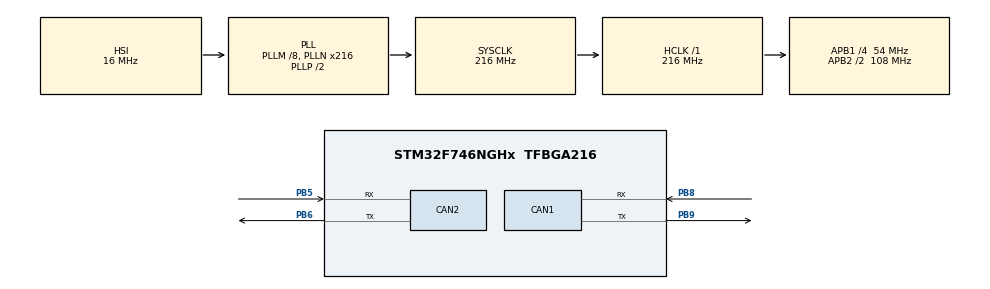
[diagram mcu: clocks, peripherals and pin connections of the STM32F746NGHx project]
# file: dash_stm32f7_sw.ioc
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CAN1.BS1=CAN_BS1_2TQ
CAN1.BS2=CAN_BS2_2TQ
CAN1.CalculateTimeQuantum=296.2962962962963
CAN1.SJW=CAN_SJW_1TQ
CAN2.BS1=CAN_BS1_2TQ
CAN2.BS2=CAN_BS2_2TQ
CAN2.CalculateTimeQuantum=296.2962962962963
Mcu.Family=STM32F7
Mcu.Name=STM32F746NGHx
Mcu.Package=TFBGA216
NVIC.PriorityGroup=NVIC_PRIORITYGROUP_4
NVIC.TIM1_UP_TIM10_IRQn=true\:0\:0\:false\:false\:true\:false\:true
NVIC.TimeBase=TIM1_UP_TIM10_IRQn
NVIC.TimeBaseIP=TIM1
PB5.Mode=Slave
PB5.Signal=CAN2_RX
PB6.Mode=Slave
PB6.Signal=CAN2_TX
PB8.Mode=Master
PB8.Signal=CAN1_RX
PB9.Mode=Master
PB9.Signal=CAN1_TX
ProjectManager.HeapSize=0x200
ProjectManager.StackSize=0x400
ProjectManager.TargetToolchain=Makefile
RCC.AHBFreq_Value=216000000
RCC.APB1CLKDivider=RCC_HCLK_DIV4
RCC.APB1Freq_Value=54000000
RCC.APB1TimFreq_Value=108000000
RCC.APB2CLKDivider=RCC_HCLK_DIV2
RCC.APB2Freq_Value=108000000
RCC.APB2TimFreq_Value=216000000
RCC.CortexFreq_Value=216000000
RCC.HCLKFreq_Value=216000000
RCC.HSE_VALUE=25000000
RCC.HSI_VALUE=16000000
RCC.LSE_VALUE=32768
RCC.PLL48CLockSelection=RCC_CLK48SOURCE_PLLSAIP
RCC.PLLI2SN=100
RCC.PLLM=8
RCC.PLLN=216
RCC.PLLQ=9
RCC.PLLSAIN=50
RCC.PLLSAIP=RCC_PLLSAIP_DIV8
RCC.SDMMCClockSelection=RCC_SDMMC1CLKSOURCE_CLK48
RCC.SYSCLKFreq_VALUE=216000000
RCC.SYSCLKSource=RCC_SYSCLKSOURCE_PLLCLK
RCC.USBFreq_Value=12500000
RCC.VCOOutputFreq_Value=432000000
VP_RTC_VS_RTC_Activate.Mode=RTC_Enabled
VP_SYS_VS_tim1.Mode=TIM1
VP_TIM2_VS_ClockSourceINT.Mode=Internal
board=32F746GDISCOVERY

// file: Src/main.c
/* USER CODE BEGIN Header */
/**
  ******************************************************************************
  * @file           : main.c
  * @brief          : Main program body
  ******************************************************************************
  * @attention
  *
  * <h2><center>&copy; Copyright (c) 2019 STMicroelectronics.
  * All rights reserved.</center></h2>
  *
  * This software component is licensed by ST under BSD 3-Clause license,
  * the "License"; You may not use this file except in compliance with the
  * License. You may obtain a copy of the License at:
  *                        opensource.org/licenses/BSD-3-Clause
  *
  ******************************************************************************
  */
/* USER CODE END Header */

#include "main.h"

/* USER CODE BEGIN Includes */
#include "../lv_conf.h"
#include "../lv_drv_conf.h"
/* USER CODE END Includes */

CAN_HandleTypeDef hcan1;
CAN_HandleTypeDef hcan2;

RTC_HandleTypeDef hrtc;

TIM_HandleTypeDef htim2;

void SystemClock_Config(void);
static void MX_GPIO_Init(void);
static void MX_RTC_Init(void);
static void MX_TIM2_Init(void);
static void MX_CAN1_Init(void);
static void MX_CAN2_Init(void);

int main(void)
{

  /* MCU Configuration--------------------------------------------------------*/

  /* Reset of all peripherals, Initializes the Flash interface and the Systick. */
  HAL_Init();

  /* Configure the system clock */
  SystemClock_Config();

  /* Initialize all configured peripherals */
  MX_GPIO_Init();
  MX_RTC_Init();
  MX_TIM2_Init();
  MX_CAN1_Init();
  MX_CAN2_Init();

  /* Infinite loop */
  while (1)
  {

  }
}

void SystemClock_Config(void)
{
  RCC_OscInitTypeDef RCC_OscInitStruct = {0};
  RCC_ClkInitTypeDef RCC_ClkInitStruct = {0};
  RCC_PeriphCLKInitTypeDef PeriphClkInitStruct = {0};

  /** Configure the main internal regulator output voltage
  */
  __HAL_RCC_PWR_CLK_ENABLE();
  __HAL_PWR_VOLTAGESCALING_CONFIG(PWR_REGULATOR_VOLTAGE_SCALE1);
  /** Initializes the CPU, AHB and APB busses clocks
  */
  RCC_OscInitStruct.OscillatorType = RCC_OSCILLATORTYPE_HSI|RCC_OSCILLATORTYPE_LSI;
  RCC_OscInitStruct.HSIState = RCC_HSI_ON;
  RCC_OscInitStruct.HSICalibrationValue = RCC_HSICALIBRATION_DEFAULT;
  RCC_OscInitStruct.LSIState = RCC_LSI_ON;
  RCC_OscInitStruct.PLL.PLLState = RCC_PLL_ON;
  RCC_OscInitStruct.PLL.PLLSource = RCC_PLLSOURCE_HSI;
  RCC_OscInitStruct.PLL.PLLM = 8;
  RCC_OscInitStruct.PLL.PLLN = 216;
  RCC_OscInitStruct.PLL.PLLP = RCC_PLLP_DIV2;
  RCC_OscInitStruct.PLL.PLLQ = 9;
  if (HAL_RCC_OscConfig(&RCC_OscInitStruct) != HAL_OK)
  {
    Error_Handler();
  }
  /** Activate the Over-Drive mode
  */
  if (HAL_PWREx_EnableOverDrive() != HAL_OK)
  {
    Error_Handler();
  }
  /** Initializes the CPU, AHB and APB busses clocks
  */
  RCC_ClkInitStruct.ClockType = RCC_CLOCKTYPE_HCLK|RCC_CLOCKTYPE_SYSCLK
                              |RCC_CLOCKTYPE_PCLK1|RCC_CLOCKTYPE_PCLK2;
  RCC_ClkInitStruct.SYSCLKSource = RCC_SYSCLKSOURCE_PLLCLK;
  RCC_ClkInitStruct.AHBCLKDivider = RCC_SYSCLK_DIV1;
  RCC_ClkInitStruct.APB1CLKDivider = RCC_HCLK_DIV4;
  RCC_ClkInitStruct.APB2CLKDivider = RCC_HCLK_DIV2;

  if (HAL_RCC_ClockConfig(&RCC_ClkInitStruct, FLASH_LATENCY_7) != HAL_OK)
  {
    Error_Handler();
  }
  PeriphClkInitStruct.PeriphClockSelection = RCC_PERIPHCLK_RTC;
  PeriphClkInitStruct.RTCClockSelection = RCC_RTCCLKSOURCE_LSI;
  if (HAL_RCCEx_PeriphCLKConfig(&PeriphClkInitStruct) != HAL_OK)
  {
    Error_Handler();
  }
}

static void MX_CAN1_Init(void)
{

  hcan1.Instance = CAN1;
  hcan1.Init.Prescaler = 16;
  hcan1.Init.Mode = CAN_MODE_NORMAL;
  hcan1.Init.SyncJumpWidth = CAN_SJW_1TQ;
  hcan1.Init.TimeSeg1 = CAN_BS1_2TQ;
  hcan1.Init.TimeSeg2 = CAN_BS2_2TQ;
  hcan1.Init.TimeTriggeredMode = DISABLE;
  hcan1.Init.AutoBusOff = DISABLE;
  hcan1.Init.AutoWakeUp = DISABLE;
  hcan1.Init.AutoRetransmission = DISABLE;
  hcan1.Init.ReceiveFifoLocked = DISABLE;
  hcan1.Init.TransmitFifoPriority = DISABLE;
  if (HAL_CAN_Init(&hcan1) != HAL_OK)
  {
    Error_Handler();
  }

}

static void MX_CAN2_Init(void)
{

  hcan2.Instance = CAN2;
  hcan2.Init.Prescaler = 16;
  hcan2.Init.Mode = CAN_MODE_NORMAL;
  hcan2.Init.SyncJumpWidth = CAN_SJW_1TQ;
  hcan2.Init.TimeSeg1 = CAN_BS1_2TQ;
  hcan2.Init.TimeSeg2 = CAN_BS2_2TQ;
  hcan2.Init.TimeTriggeredMode = DISABLE;
  hcan2.Init.AutoBusOff = DISABLE;
  hcan2.Init.AutoWakeUp = DISABLE;
  hcan2.Init.AutoRetransmission = DISABLE;
  hcan2.Init.ReceiveFifoLocked = DISABLE;
  hcan2.Init.TransmitFifoPriority = DISABLE;
  if (HAL_CAN_Init(&hcan2) != HAL_OK)
  {
    Error_Handler();
  }

}

static void MX_RTC_Init(void)
{

  /** Initialize RTC Only
  */
  hrtc.Instance = RTC;
  hrtc.Init.HourFormat = RTC_HOURFORMAT_24;
  hrtc.Init.AsynchPrediv = 127;
  hrtc.Init.SynchPrediv = 255;
  hrtc.Init.OutPut = RTC_OUTPUT_DISABLE;
  hrtc.Init.OutPutPolarity = RTC_OUTPUT_POLARITY_HIGH;
  hrtc.Init.OutPutType = RTC_OUTPUT_TYPE_OPENDRAIN;
  if (HAL_RTC_Init(&hrtc) != HAL_OK)
  {
    Error_Handler();
  }

}

static void MX_TIM2_Init(void)
{

  TIM_ClockConfigTypeDef sClockSourceConfig = {0};
  TIM_MasterConfigTypeDef sMasterConfig = {0};

  htim2.Instance = TIM2;
  htim2.Init.Prescaler = 0;
  htim2.Init.CounterMode = TIM_COUNTERMODE_UP;
  htim2.Init.Period = 0;
  htim2.Init.ClockDivision = TIM_CLOCKDIVISION_DIV1;
  htim2.Init.AutoReloadPreload = TIM_AUTORELOAD_PRELOAD_DISABLE;
  if (HAL_TIM_Base_Init(&htim2) != HAL_OK)
  {
    Error_Handler();
  }
  sClockSourceConfig.ClockSource = TIM_CLOCKSOURCE_INTERNAL;
  if (HAL_TIM_ConfigClockSource(&htim2, &sClockSourceConfig) != HAL_OK)
  {
    Error_Handler();
  }
  sMasterConfig.MasterOutputTrigger = TIM_TRGO_RESET;
  sMasterConfig.MasterSlaveMode = TIM_MASTERSLAVEMODE_DISABLE;
  if (HAL_TIMEx_MasterConfigSynchronization(&htim2, &sMasterConfig) != HAL_OK)
  {
    Error_Handler();
  }

}

static void MX_GPIO_Init(void)
{
  GPIO_InitTypeDef GPIO_InitStruct = {0};

  /* GPIO Ports Clock Enable */
  __HAL_RCC_GPIOE_CLK_ENABLE();
  __HAL_RCC_GPIOG_CLK_ENABLE();
  __HAL_RCC_GPIOB_CLK_ENABLE();
  __HAL_RCC_GPIOD_CLK_ENABLE();
  __HAL_RCC_GPIOC_CLK_ENABLE();
  __HAL_RCC_GPIOA_CLK_ENABLE();
  __HAL_RCC_GPIOJ_CLK_ENABLE();
  __HAL_RCC_GPIOI_CLK_ENABLE();
  __HAL_RCC_GPIOK_CLK_ENABLE();
  __HAL_RCC_GPIOF_CLK_ENABLE();
  __HAL_RCC_GPIOH_CLK_ENABLE();

  /*Configure GPIO pins : PE4 PE3 PE2 PE1
                           PE0 PE5 PE6 PE8
                           PE9 PE11 PE14 PE7
                           PE10 PE12 PE15 PE13 */
  GPIO_InitStruct.Pin = GPIO_PIN_4|GPIO_PIN_3|GPIO_PIN_2|GPIO_PIN_1
                          |GPIO_PIN_0|GPIO_PIN_5|GPIO_PIN_6|GPIO_PIN_8
                          |GPIO_PIN_9|GPIO_PIN_11|GPIO_PIN_14|GPIO_PIN_7
                          |GPIO_PIN_10|GPIO_PIN_12|GPIO_PIN_15|GPIO_PIN_13;
  GPIO_InitStruct.Mode = GPIO_MODE_ANALOG;
  GPIO_InitStruct.Pull = GPIO_NOPULL;
  HAL_GPIO_Init(GPIOE, &GPIO_InitStruct);

  /*Configure GPIO pins : PG14 PG13 PG15 PG11
                           PG12 PG10 PG9 PG8
                           PG7 PG6 PG1 PG3
                           PG2 PG0 PG5 PG4 */
  GPIO_InitStruct.Pin = GPIO_PIN_14|GPIO_PIN_13|GPIO_PIN_15|GPIO_PIN_11
                          |GPIO_PIN_12|GPIO_PIN_10|GPIO_PIN_9|GPIO_PIN_8
                          |GPIO_PIN_7|GPIO_PIN_6|GPIO_PIN_1|GPIO_PIN_3
                          |GPIO_PIN_2|GPIO_PIN_0|GPIO_PIN_5|GPIO_PIN_4;
  GPIO_InitStruct.Mode = GPIO_MODE_ANALOG;
  GPIO_InitStruct.Pull = GPIO_NOPULL;
  HAL_GPIO_Init(GPIOG, &GPIO_InitStruct);

  /*Configure GPIO pins : PB4 PB3 PB7 PB13
                           PB12 PB2 PB10 PB1
                           PB0 PB11 PB14 PB15 */
  GPIO_InitStruct.Pin = GPIO_PIN_4|GPIO_PIN_3|GPIO_PIN_7|GPIO_PIN_13
                          |GPIO_PIN_12|GPIO_PIN_2|GPIO_PIN_10|GPIO_PIN_1
                          |GPIO_PIN_0|GPIO_PIN_11|GPIO_PIN_14|GPIO_PIN_15;
  GPIO_InitStruct.Mode = GPIO_MODE_ANALOG;
  GPIO_InitStruct.Pull = GPIO_NOPULL;
  HAL_GPIO_Init(GPIOB, &GPIO_InitStruct);

  /*Configure GPIO pins : PD7 PD6 PD0 PD5
                           PD3 PD1 PD4 PD2
                           PD15 PD10 PD14 PD9
                           PD8 PD12 PD13 PD11 */
  GPIO_InitStruct.Pin = GPIO_PIN_7|GPIO_PIN_6|GPIO_PIN_0|GPIO_PIN_5
                          |GPIO_PIN_3|GPIO_PIN_1|GPIO_PIN_4|GPIO_PIN_2
                          |GPIO_PIN_15|GPIO_PIN_10|GPIO_PIN_14|GPIO_PIN_9
                          |GPIO_PIN_8|GPIO_PIN_12|GPIO_PIN_13|GPIO_PIN_11;
  GPIO_InitStruct.Mode = GPIO_MODE_ANALOG;
  GPIO_InitStruct.Pull = GPIO_NOPULL;
  HAL_GPIO_Init(GPIOD, &GPIO_InitStruct);

  /*Configure GPIO pins : PC12 PC11 PC10 PC13
                           PC14 PC15 PC9 PC8
                           PC7 PC6 PC3 PC0
                           PC1 PC2 PC4 PC5 */
  GPIO_InitStruct.Pin = GPIO_PIN_12|GPIO_PIN_11|GPIO_PIN_10|GPIO_PIN_13
                          |GPIO_PIN_14|GPIO_PIN_15|GPIO_PIN_9|GPIO_PIN_8
                          |GPIO_PIN_7|GPIO_PIN_6|GPIO_PIN_3|GPIO_PIN_0
                          |GPIO_PIN_1|GPIO_PIN_2|GPIO_PIN_4|GPIO_PIN_5;
  GPIO_InitStruct.Mode = GPIO_MODE_ANALOG;
  GPIO_InitStruct.Pull = GPIO_NOPULL;
  HAL_GPIO_Init(GPIOC, &GPIO_InitStruct);

  /*Configure GPIO pins : PA15 PA14 PA13 PA12
                           PA11 PA10 PA9 PA8
                           PA1 PA0 PA4 PA2
                           PA6 PA5 PA3 PA7 */
  GPIO_InitStruct.Pin = GPIO_PIN_15|GPIO_PIN_14|GPIO_PIN_13|GPIO_PIN_12
                          |GPIO_PIN_11|GPIO_PIN_10|GPIO_PIN_9|GPIO_PIN_8
                          |GPIO_PIN_1|GPIO_PIN_0|GPIO_PIN_4|GPIO_PIN_2
                          |GPIO_PIN_6|GPIO_PIN_5|GPIO_PIN_3|GPIO_PIN_7;
  GPIO_InitStruct.Mode = GPIO_MODE_ANALOG;
  GPIO_InitStruct.Pull = GPIO_NOPULL;
  HAL_GPIO_Init(GPIOA, &GPIO_InitStruct);

  /*Configure GPIO pins : PJ13 PJ12 PJ14 PJ15
                           PJ11 PJ8 PJ10 PJ7
                           PJ9 PJ6 PJ4 PJ5
                           PJ3 PJ2 PJ0 PJ1 */
  GPIO_InitStruct.Pin = GPIO_PIN_13|GPIO_PIN_12|GPIO_PIN_14|GPIO_PIN_15
                          |GPIO_PIN_11|GPIO_PIN_8|GPIO_PIN_10|GPIO_PIN_7
                          |GPIO_PIN_9|GPIO_PIN_6|GPIO_PIN_4|GPIO_PIN_5
                          |GPIO_PIN_3|GPIO_PIN_2|GPIO_PIN_0|GPIO_PIN_1;
  GPIO_InitStruct.Mode = GPIO_MODE_ANALOG;
  GPIO_InitStruct.Pull = GPIO_NOPULL;
  HAL_GPIO_Init(GPIOJ, &GPIO_InitStruct);

  /*Configure GPIO pins : PI8 PI4 PI3 PI2
                           PI5 PI7 PI10 PI6
                           PI1 PI12 PI9 PI0
                           PI11 PI13 PI15 PI14 */
  GPIO_InitStruct.Pin = GPIO_PIN_8|GPIO_PIN_4|GPIO_PIN_3|GPIO_PIN_2
                          |GPIO_PIN_5|GPIO_PIN_7|GPIO_PIN_10|GPIO_PIN_6
                          |GPIO_PIN_1|GPIO_PIN_12|GPIO_PIN_9|GPIO_PIN_0
                          |GPIO_PIN_11|GPIO_PIN_13|GPIO_PIN_15|GPIO_PIN_14;
  GPIO_InitStruct.Mode = GPIO_MODE_ANALOG;
  GPIO_InitStruct.Pull = GPIO_NOPULL;
  HAL_GPIO_Init(GPIOI, &GPIO_InitStruct);

  /*Configure GPIO pins : PK7 PK6 PK5 PK4
                           PK3 PK1 PK2 PK0 */
  GPIO_InitStruct.Pin = GPIO_PIN_7|GPIO_PIN_6|GPIO_PIN_5|GPIO_PIN_4
                          |GPIO_PIN_3|GPIO_PIN_1|GPIO_PIN_2|GPIO_PIN_0;
  GPIO_InitStruct.Mode = GPIO_MODE_ANALOG;
  GPIO_InitStruct.Pull = GPIO_NOPULL;
  HAL_GPIO_Init(GPIOK, &GPIO_InitStruct);

  /*Configure GPIO pins : PF0 PF1 PF2 PF3
                           PF4 PF7 PF6 PF5
                           PF10 PF9 PF8 PF12
                           PF15 PF13 PF14 PF11 */
  GPIO_InitStruct.Pin = GPIO_PIN_0|GPIO_PIN_1|GPIO_PIN_2|GPIO_PIN_3
                          |GPIO_PIN_4|GPIO_PIN_7|GPIO_PIN_6|GPIO_PIN_5
                          |GPIO_PIN_10|GPIO_PIN_9|GPIO_PIN_8|GPIO_PIN_12
                          |GPIO_PIN_15|GPIO_PIN_13|GPIO_PIN_14|GPIO_PIN_11;
  GPIO_InitStruct.Mode = GPIO_MODE_ANALOG;
  GPIO_InitStruct.Pull = GPIO_NOPULL;
  HAL_GPIO_Init(GPIOF, &GPIO_InitStruct);

  /*Configure GPIO pins : PH15 PH13 PH14 PH0
                           PH1 PH4 PH5 PH3
                           PH2 PH12 PH7 PH9
                           PH11 PH6 PH8 PH10 */
  GPIO_InitStruct.Pin = GPIO_PIN_15|GPIO_PIN_13|GPIO_PIN_14|GPIO_PIN_0
                          |GPIO_PIN_1|GPIO_PIN_4|GPIO_PIN_5|GPIO_PIN_3
                          |GPIO_PIN_2|GPIO_PIN_12|GPIO_PIN_7|GPIO_PIN_9
                          |GPIO_PIN_11|GPIO_PIN_6|GPIO_PIN_8|GPIO_PIN_10;
  GPIO_InitStruct.Mode = GPIO_MODE_ANALOG;
  GPIO_InitStruct.Pull = GPIO_NOPULL;
  HAL_GPIO_Init(GPIOH, &GPIO_InitStruct);

}

void HAL_TIM_PeriodElapsedCallback(TIM_HandleTypeDef *htim)
{
  if (htim->Instance == TIM1) {
    HAL_IncTick();
  }
}

void Error_Handler(void)
{
}

/************************ (C) COPYRIGHT STMicroelectronics *****END OF FILE****/
